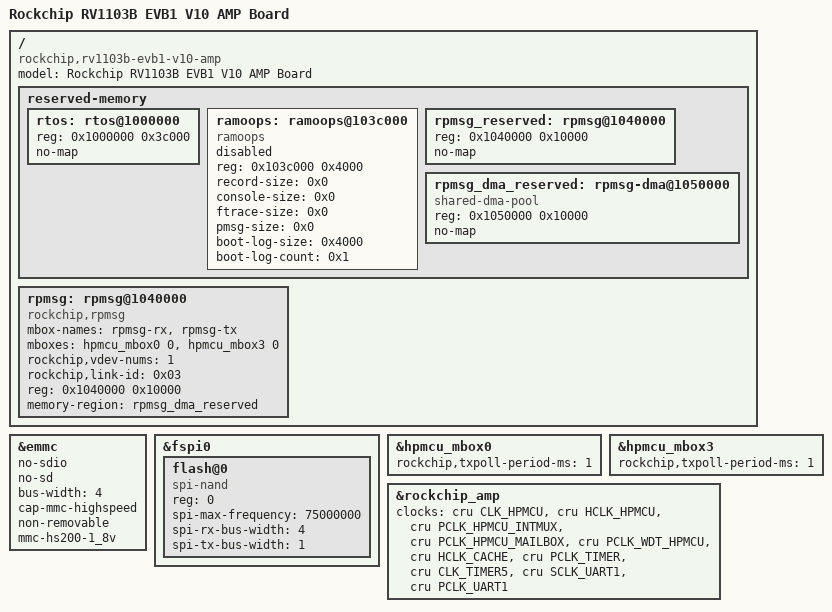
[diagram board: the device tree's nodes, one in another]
// SPDX-License-Identifier: (GPL-2.0+ OR MIT)
/*
 * Copyright (c) 2025 Rockchip Electronics Co., Ltd.
 */

/dts-v1/;

#include "rv1103b.dtsi"
#include "rv1103b-evb.dtsi"
#include "rv1106b-amp.dtsi"

/ {
	model = "Rockchip RV1103B EVB1 V10 AMP Board";
	compatible = "rockchip,rv1103b-evb1-v10-amp", "rockchip,rv1103b";

	reserved-memory {
		#address-cells = <1>;
		#size-cells = <1>;
		ranges;

		rtos: rtos@1000000 {
			reg = <0x1000000 0x3c000>;
			no-map;
		};

		/* Reserved for mcu log via pstore */
		ramoops: ramoops@103c000 {
			compatible = "ramoops";
			reg = <0x103c000 0x4000>;
			record-size = <0x0>;
			console-size = <0x0>;
			ftrace-size = <0x0>;
			pmsg-size = <0x0>;
			boot-log-size = <0x4000>;
			boot-log-count = <0x1>;
			status = "disabled";
		};

		rpmsg_reserved: rpmsg@1040000 {
			reg = <0x1040000 0x10000>;
			no-map;
		};

		rpmsg_dma_reserved: rpmsg-dma@1050000 {
			compatible = "shared-dma-pool";
			reg = <0x1050000 0x10000>;
			no-map;
		};
	};

	rpmsg: rpmsg@1040000 {
		compatible = "rockchip,rpmsg";
		mbox-names = "rpmsg-rx", "rpmsg-tx";
		mboxes = <&hpmcu_mbox0 0 &hpmcu_mbox3 0>;
		rockchip,vdev-nums = <1>;
		rockchip,link-id = <0x03>;
		reg = <0x1040000 0x10000>;
		memory-region = <&rpmsg_dma_reserved>;
	};

};

&emmc {
	no-sdio;
	no-sd;
	bus-width = <4>;
	cap-mmc-highspeed;
	non-removable;
	mmc-hs200-1_8v;
	status = "okay";
};

&fspi0 {
	status = "okay";

	flash@0 {
		compatible = "spi-nand";
		reg = <0>;
		spi-max-frequency = <75000000>;
		spi-rx-bus-width = <4>;
		spi-tx-bus-width = <1>;
	};
};

&hpmcu_mbox0 {
	rockchip,txpoll-period-ms = <1>;
	status = "okay";
};

&hpmcu_mbox3 {
	rockchip,txpoll-period-ms = <1>;
	status = "okay";
};

&rockchip_amp {
	clocks = <&cru CLK_HPMCU>, <&cru HCLK_HPMCU>,
		 <&cru PCLK_HPMCU_INTMUX>, <&cru PCLK_HPMCU_MAILBOX>,
		 <&cru PCLK_WDT_HPMCU>, <&cru HCLK_CACHE>,
		 <&cru PCLK_TIMER>, <&cru CLK_TIMER5>,
		 <&cru SCLK_UART1>, <&cru PCLK_UART1>;
};
